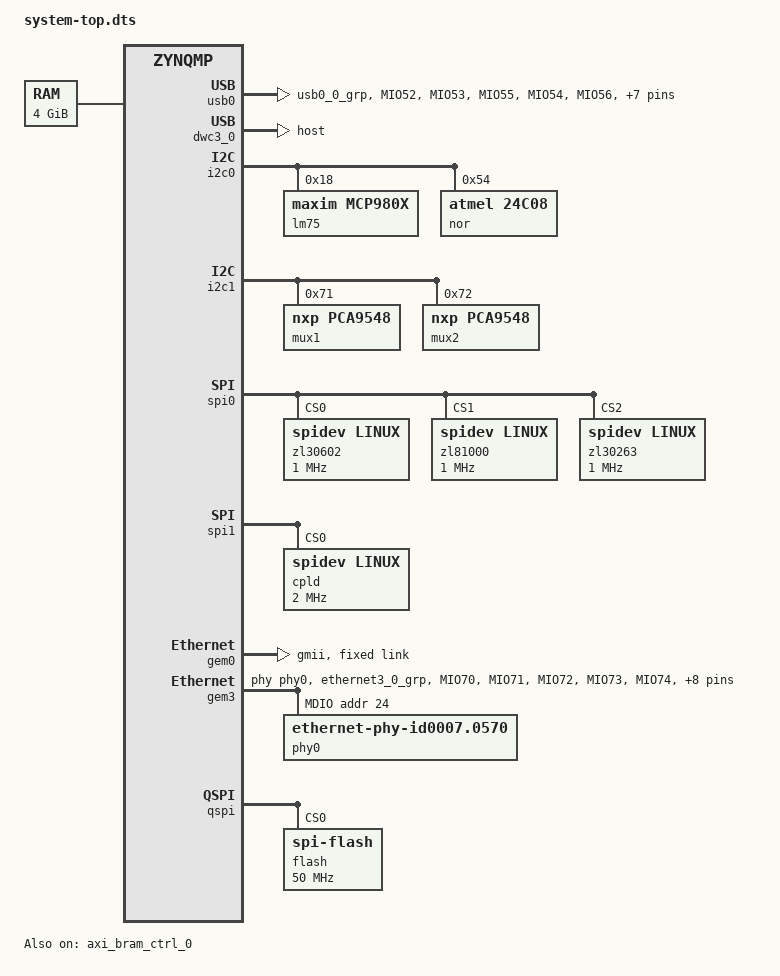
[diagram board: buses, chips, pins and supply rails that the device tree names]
/*
 * CAUTION: This file is automatically generated by Xilinx.
 * Version: XSCT 2022.1
 * Today is: Wed Sep 28 20:00:52 2022
 */


/dts-v1/;
#include "zynqmp.dtsi"
#include "zynqmp-clk-ccf.dtsi"
//#include "pl.dtsi"
#include "pcw.dtsi"
/ {
	chosen {
		bootargs = "earlycon clk_ignore_unused";
		stdout-path = "serial0:115200n8";
	};
	memory {
		device_type = "memory";
		reg = <0x0 0x0 0x0 0x7ff00000>, <0x00000008 0x00000000 0x0 0x80000000>;
	};
};

#include "gpio.h"
#include "pinctrl-zynqmp.h"
#include "phy.h"

/ {
	aliases {
		gpio0 = &gpio;
		//mmc0 = &sdhci1;
		mmc0 = &sdhci0; /* guy - fix the dtb for u-boot ! */
                ethernet0 = &gem3;
                ethernet1 = &gem0;
                i2c0 = &i2c0;
                i2c1 = &i2c1;
                serial0 = &uart0;
                serial1 = &uart1;
                spi0 = &qspi;
                spi1 = &spi1;
		//rtc0 = &rtc;
		usb0 = &usb0;
	};

};


&usb0 {
  status = "okay";
  pinctrl-names = "default";
  pinctrl-0 = <&pinctrl_usb0_default>;

};

&dwc3_0 {
	status = "okay";
	dr_mode = "host";
	snps,usb3_lpm_capable;
	//phy-names = "usb3-phy";
	//phys = <&lane2 PHY_TYPE_USB3 0 2 26000000>;
	maximum-speed = "super-speed";
};
&i2c0 {
    status = "okay";
    //gpios = <&gpio1 28 2   /* SCL - open drain, active low */
    // &gpio1 31 2>; /* SDA - driven, active high */

    lm75: mcp9808@18 {
        compatible = "maxim,mcp980x";
        reg = <0x18>;
        name = "mcp9808";
    };

    nor: at24c08@54 {
         compatible = "atmel,24c08";
         reg = <0x54>; /* 54-57 */
         name = "at24c08";
     };
};

&i2c1 {
    status = "okay";
/*
    pinctrl-names = "default", "gpio";
    pinctrl-0 = <&pinctrl_i2c1_default>;
    pinctrl-1 = <&pinctrl_i2c1_gpio>;
    scl-gpios = <&gpio 48 GPIO_ACTIVE_HIGH>;
    sda-gpios = <&gpio 49 GPIO_ACTIVE_HIGH>;
*/
    mux1@71 {
        compatible = "nxp,pca9548";
        reg = <0x71>;
        #address-cells = <1>;
        #size-cells = <0>;
        i2c-mux-idle-disconnect;

        channel0@0 {
            #address-cells = <1>;
            #size-cells = <0>;
            reg = <0x0>;
        };
        channel1@1 {
            #address-cells = <1>;
            #size-cells = <0>;
            reg = <0x1>;
        };
        channel2@2 {
            #address-cells = <1>;
            #size-cells = <0>;
            reg = <0x2>;
        };
        channel3@3 {
            #address-cells = <1>;
            #size-cells = <0>;
            reg = <0x3>;
        };
        channel4@4 {
            #address-cells = <1>;
            #size-cells = <0>;
            reg = <0x4>;
        };
        channel5@5 {
            #address-cells = <1>;
            #size-cells = <0>;
            reg = <0x5>;
        };
        channel6@6 {
            #address-cells = <1>;
            #size-cells = <0>;
            reg = <0x6>;
        };
        channel7@7 {
            #address-cells = <1>;
            #size-cells = <0>;
            reg = <0x7>;
        };
    };

    mux2@72 {
        compatible = "nxp,pca9548";
        reg = <0x72>;
        #address-cells = <1>;
        #size-cells = <0>;
        i2c-mux-idle-disconnect;

        channel0@0 {
            #address-cells = <1>;
            #size-cells = <0>;
            reg = <0x0>;
        };
        channel1@1 {
            #address-cells = <1>;
            #size-cells = <0>;
            reg = <0x1>;
        };
        channel2@2 {
            #address-cells = <1>;
            #size-cells = <0>;
            reg = <0x2>;
        };
        channel3@3 {
            #address-cells = <1>;
            #size-cells = <0>;
            reg = <0x3>;
        };
        channel4@4 {
            #address-cells = <1>;
            #size-cells = <0>;
            reg = <0x4>;
        };
        channel5@5 {
            #address-cells = <1>;
            #size-cells = <0>;
            reg = <0x5>;
        };
        channel6@6 {
            #address-cells = <1>;
            #size-cells = <0>;
            reg = <0x6>;
        };
        channel7@7 {
            #address-cells = <1>;
            #size-cells = <0>;
            reg = <0x7>;
        };
    };

};

&spi0 {
    status = "okay";
    /*spi-num-chipselects = <0x3>;*/
    num-cs = <0x3>;
    bus-num = <1>;

    zl30602: cs0@1 {
        compatible = "spidev,linux";
        spi-max-frequency = <1000000>;
        fsl,spi-cs-sck-delay = <50>;
        fsl,spi-sck-cs-delay = <50>;
        mode = <0>;
        reg = <0>;
    };

    zl81000: cs1@1 {
        compatible = "spidev,linux";
        spi-max-frequency = <1000000>;
        fsl,spi-cs-sck-delay = <50>;
        fsl,spi-sck-cs-delay = <50>;
        mode = <0>;
        reg = <1>;
    };

    zl30263: cs2@1 {
        compatible = "spidev,linux";
        spi-max-frequency = <1000000>;
        fsl,spi-cs-sck-delay = <105>;
        fsl,spi-sck-cs-delay = <110>;
        mode = <0>;
        reg = <2>;
    };

};


&spi1 {
    status = "okay";
    /*spi-num-chipselects = <0x3>;*/
    num-cs = <0x1>;
    bus-num = <0>;

    cpld: cs0@0 {
        compatible = "spidev,linux";
        spi-max-frequency = <2000000>;
        fsl,spi-cs-sck-delay = <50>;
        fsl,spi-sck-cs-delay = <50>;
        mode = <0>;
        reg = <0>;
        spi-cpha = <1>;
        spi-cpol = <0>;
    };
};


&pinctrl0 {
	status = "okay";
            pinctrl_usb0_default: usb0-default {
            mux {
                    groups = "usb0_0_grp";
                    function = "usb0";
            };

            conf {
                    groups = "usb0_0_grp";
                    slew-rate = <SLEW_RATE_SLOW>;
                    io-standard = <IO_STANDARD_LVCMOS18>;
            };

            conf-rx {
                    pins = "MIO52", "MIO53", "MIO55";
                    bias-high-impedance;
            };

            conf-tx {
                    pins = "MIO54", "MIO56", "MIO57", "MIO58", "MIO59",
                           "MIO60", "MIO61", "MIO62", "MIO63";
                    bias-disable;
            };
    };

	pinctrl_gem3_default: gem3-default {
		mux {
			function = "ethernet3";
			groups = "ethernet3_0_grp";
		};

		conf {
			groups = "ethernet3_0_grp";
			slew-rate = <1>;
			io-standard = <1>;
		};

		conf-rx {
			pins = "MIO70", "MIO71", "MIO72", "MIO73", "MIO74",
									"MIO75";
			bias-high-impedance;
			low-power-disable;
		};

		conf-tx {
			pins = "MIO64", "MIO65", "MIO66", "MIO67", "MIO68",
									"MIO69";
			bias-disable;
			low-power-enable;
		};

		mux-mdio {
			function = "mdio3";
			groups = "mdio3_0_grp";
		};

		conf-mdio {
			groups = "mdio3_0_grp";
			slew-rate = <1>;
			io-standard = <1>;
			bias-disable;
		};
	};

};

&gem0 {
 compatible = "cdns,zynqmp-gem", "cdns,gem";
 phy-mode = "gmii";
 //phy-mode = "moca";
 //is-internal-pcspma;
 status = "okay";
        fixed-link {
                speed = <1000>;
                full-duplex;
                //pause;
        };
 //local-mac-address = [00 0a 35 00 00 00];
};


/* Information and example for Microsemi - vsc8531 Giga bit ethernet phy.
   It can be found in the kernel under Documentation/devicetree/bindings/net/mscc-phy-vsc8531.txt 
   Exmaple:
        vsc8531_0: ethernet-phy@0 {
                compatible = "ethernet-phy-id0007.0570"
                vsc8531,vddmac		= <3300>;
                vsc8531,edge-slowdown	= <21>;
        };*/

&gem3 {
 compatible = "cdns,zynqmp-gem", "cdns,gem"; 
 status = "okay";
 phy-handle = <&phy0>;
 pinctrl-0 = <&pinctrl_gem3_default>;

  mdio {
     #address-cells = <0x1>;
     #size-cells = <0x0>;
     phy0: ethernet-phy@18 {
      compatible = "ethernet-phy-id0007.0570";
      reg = <0x18>;
     };
  };
 
  //local-mac-address = [00 0a 35 00 00 01];

};

&amba {
        //status = "okay";
        axi_bram_ctrl_0: axi_bram_ctrl@a0000000 {
                /* This is a place holder node for a custom IP, user may need to update the entries */
                status = "okay";
                clock-names = "s_axi_aclk";
                clocks = <&zynqmp_clk 71>;
                compatible = "uio_pdrv_genirq"; 
                reg = <0x0 0xa0000000 0x0 0x4000000>;
                xlnx,bram-addr-width = <0xb>;
                xlnx,bram-inst-mode = "EXTERNAL";
                xlnx,ecc = <0x0>;
                xlnx,ecc-onoff-reset-value = <0x0>;
                xlnx,ecc-type = <0x0>;
                xlnx,fault-inject = <0x0>;
                xlnx,memory-depth = <0x800>;
                xlnx,rd-cmd-optimization = <0x0>;
                xlnx,read-latency = <0x1>;
                xlnx,s-axi-ctrl-addr-width = <0x20>;
                xlnx,s-axi-ctrl-data-width = <0x20>;
                xlnx,s-axi-id-width = <0x1>;
                xlnx,s-axi-supports-narrow-burst = <0x0>;
                xlnx,single-port-bram = <0x0>;
        };
};

&qspi {
	status = "okay";
	flash@0 {
		compatible = "spi-flash", "jedec,spi-nor"; /* 32MB */
		#address-cells = <1>;
		#size-cells = <1>;
		reg = <0x0>;
		spi-tx-bus-width = <1>;
		spi-rx-bus-width = <4>; /* FIXME also DUAL configuration possible */
		spi-max-frequency = <50000000>; /* Based on DC1 spec */
	};
};

/*&amba_pl {
        status = "okay";
        axi_bram_ctrl@a0000000 {
               compatible = "uio_pdrv_genirq"; 
               //compatible = "generic-uio";
               reg = <0x0 0xa0000000 0x0 0x2000>;
               status = "okay";
        };
};*/

/*&axi_bram_ctrl {
       compatible = "uio_pdrv_genirq"; 
       //compatible = "generic-uio";
       reg = <0x0 0xa0000000 0x0 0x2000>;
       status = "okay";
};*/


